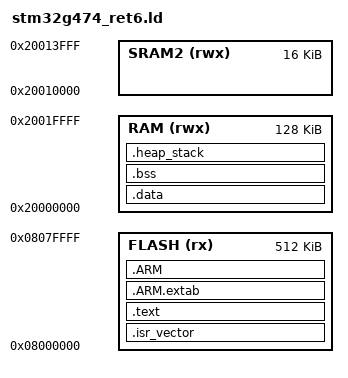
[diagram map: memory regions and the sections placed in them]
/*
 * linker script for STM32G474RET6 (LQFP64)
 * 512 KB Flash, 128 KB SRAM1, 16 KB SRAM2 (CCM)
 */

ENTRY(Reset_Handler)

MEMORY
{
    FLASH (rx) : ORIGIN = 0x08000000, LENGTH = 512K
    RAM   (rwx) : ORIGIN = 0x20000000, LENGTH = 128K
    SRAM2 (rwx) : ORIGIN = 0x20010000, LENGTH = 16K
}

_estack = ORIGIN(RAM) + LENGTH(RAM);

SECTIONS
{
    .isr_vector :
    {
        . = ALIGN(4);
        KEEP(*(.isr_vector))
        . = ALIGN(4);
    } > FLASH

    .text :
    {
        . = ALIGN(4);
        *(.text)
        *(.text*)
        *(.rodata)
        *(.rodata*)
        . = ALIGN(4);
        _etext = .;
    } > FLASH

    .ARM.extab :
    {
        *(.ARM.extab* .gnu.linkonce.armextab.*)
    } > FLASH

    .ARM :
    {
        *(.ARM.exidx*)
    } > FLASH

    .data : AT (_etext)
    {
        . = ALIGN(4);
        _sdata = .;
        *(.data)
        *(.data*)
        . = ALIGN(4);
        _edata = .;
    } > RAM

    .bss :
    {
        . = ALIGN(4);
        _sbss = .;
        *(.bss)
        *(.bss*)
        *(COMMON)
        . = ALIGN(4);
        _ebss = .;
    } > RAM

    .heap_stack :
    {
        . = ALIGN(8);
        . = . + 0x400;
        . = ALIGN(8);
    } > RAM
}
